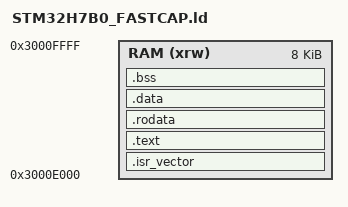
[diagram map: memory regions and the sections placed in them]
ENTRY(fastcap_frame)

MEMORY
{
  /* Code region in D2 AHB-SRAM1 (0x30000000-0x30010000, 64 KB), above the
     fastcap data buffers: tile-hash 0x30000000, YCC scratch 0x30000400,
     payload 0x30002400 (47 KB). Leaves 8 KB here for code + bss (binary ~3.7 KB).
     The host enables the D2 clock (RCC_AHB2ENR) before loading this binary. */
  RAM (xrw) : ORIGIN = 0x3000E000, LENGTH = 8K
}

_estack = ORIGIN(RAM) + LENGTH(RAM);

SECTIONS
{
  .isr_vector :
  {
    . = ALIGN(4);
    KEEP(*(.isr_vector))
    . = ALIGN(4);
  } >RAM

  .text :
  {
    . = ALIGN(4);
    *(.text)
    *(.text*)
    *(.glue_7)
    *(.glue_7t)
    *(.eh_frame)
    . = ALIGN(4);
    _etext = .;
  } >RAM

  .rodata :
  {
    . = ALIGN(4);
    *(.rodata)
    *(.rodata*)
    . = ALIGN(4);
  } >RAM

  _sidata = LOADADDR(.data);

  .data :
  {
    . = ALIGN(4);
    _sdata = .;
    *(.data)
    *(.data*)
    . = ALIGN(4);
    _edata = .;
  } >RAM

  .bss :
  {
    . = ALIGN(4);
    _sbss = .;
    __bss_start__ = _sbss;
    *(.bss)
    *(.bss*)
    *(COMMON)
    . = ALIGN(4);
    _ebss = .;
    __bss_end__ = _ebss;
  } >RAM

  /DISCARD/ :
  {
    libc.a ( * )
    libm.a ( * )
    libgcc.a ( * )
  }

  .ARM.attributes 0 : { *(.ARM.attributes) }
}
